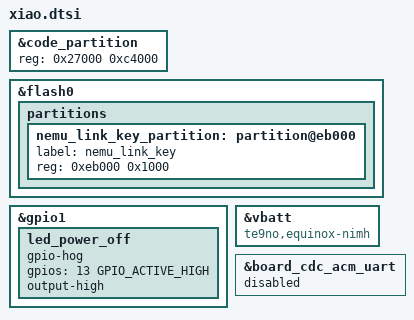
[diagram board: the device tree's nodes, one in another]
/* One private erase page, outside application and existing settings. */
&code_partition { reg = <0x27000 0xc4000>; };
&flash0 {
    partitions {
        nemu_link_key_partition: partition@eb000 {
            label = "nemu_link_key";
            reg = <0xeb000 0x1000>;
        };
    };
};
/* LED animations are not part of this receiver-based variant. Keep power off. */
&gpio1 {
    led_power_off { gpio-hog; gpios = <13 GPIO_ACTIVE_HIGH>; output-high; };
};

&vbatt { compatible = "te9no,equinox-nimh"; };

/* Use the explicitly named bootloader CDC instead of an unused board CDC. */
&board_cdc_acm_uart { status = "disabled"; };
